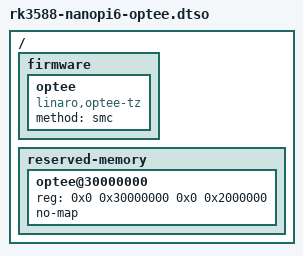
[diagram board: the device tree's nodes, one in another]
/dts-v1/;
/plugin/;

/ {
    fragment@1 {
        target-path = "/";
        __overlay__ {
            firmware {
                optee {
                    compatible = "linaro,optee-tz";
                    method = "smc";
                };
            };

            reserved-memory {
                #address-cells = <2>;
                #size-cells = <2>;
                ranges;

                optee@30000000 {
                    reg = <0x0 0x30000000 0x0 0x2000000>;
                    no-map;
                };
            };
        };
    };
};

